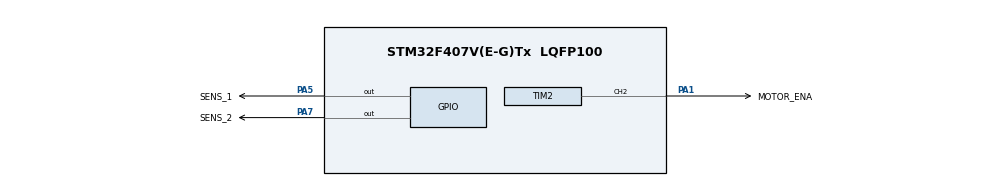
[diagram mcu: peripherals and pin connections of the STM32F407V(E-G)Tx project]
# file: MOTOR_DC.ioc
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Mcu.Family=STM32F4
Mcu.Name=STM32F407V(E-G)Tx
Mcu.Package=LQFP100
NVIC.PriorityGroup=NVIC_PRIORITYGROUP_0
PA1.GPIO_Label=MOTOR_ENA
PA1.Signal=S_TIM2_CH2
PA13.Mode=Serial_Wire
PA13.Signal=SYS_JTMS-SWDIO
PA14.Mode=Serial_Wire
PA14.Signal=SYS_JTCK-SWCLK
PA5.GPIO_Label=SENS_1
PA5.Signal=GPIO_Output
PA7.GPIO_Label=SENS_2
PA7.Signal=GPIO_Output
PH0-OSC_IN.Mode=HSE-External-Oscillator
PH0-OSC_IN.Signal=RCC_OSC_IN
PH1-OSC_OUT.Mode=HSE-External-Oscillator
PH1-OSC_OUT.Signal=RCC_OSC_OUT
ProjectManager.HeapSize=0x200
ProjectManager.StackSize=0x400
ProjectManager.TargetToolchain=STM32CubeIDE
RCC.48MHZClocksFreq_Value=48000000
RCC.AHBFreq_Value=168000000
RCC.APB1CLKDivider=RCC_HCLK_DIV4
RCC.APB1Freq_Value=42000000
RCC.APB1TimFreq_Value=84000000
RCC.APB2CLKDivider=RCC_HCLK_DIV2
RCC.APB2Freq_Value=84000000
RCC.APB2TimFreq_Value=168000000
RCC.CortexFreq_Value=168000000
RCC.HCLKFreq_Value=168000000
RCC.HSE_VALUE=8000000
RCC.HSI_VALUE=16000000
RCC.LSE_VALUE=32768
RCC.PLLM=8
RCC.PLLN=336
RCC.PLLQ=7
RCC.PLLSourceVirtual=RCC_PLLSOURCE_HSE
RCC.SYSCLKFreq_VALUE=168000000
RCC.SYSCLKSource=RCC_SYSCLKSOURCE_PLLCLK
RCC.VCOOutputFreq_Value=336000000
SH.S_TIM2_CH2.0=TIM2_CH2,PWM Generation2 CH2
TIM2.AutoReloadPreload=TIM_AUTORELOAD_PRELOAD_ENABLE
TIM2.Channel-PWM\ Generation2\ CH2=TIM_CHANNEL_2
TIM2.Period=625
TIM2.Prescaler=200
VP_TIM2_VS_ClockSourceINT.Mode=Internal
board=STM32F407G-DISC1

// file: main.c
#include "main.h"

/* USER CODE BEGIN Includes */
#include "string.h"
#include "stdlib.h"
#include "MOTOR_DC.h"
/* USER CODE END Includes */

TIM_HandleTypeDef htim2;

/* USER CODE BEGIN PV */
My_Motor_DC myMotor;
/* USER CODE END PV */

void SystemClock_Config(void);
static void MX_GPIO_Init(void);
static void MX_TIM2_Init(void);

int main(void)
{

  /* MCU Configuration--------------------------------------------------------*/

  /* Reset of all peripherals, Initializes the Flash interface and the Systick. */
  HAL_Init();

  /* Configure the system clock */
  SystemClock_Config();

  /* Initialize all configured peripherals */
  MX_GPIO_Init();
  MX_TIM2_Init();
  /* USER CODE BEGIN 2 */
  MOTOR_INIT(&myMotor, &htim2, TIM_CHANNEL_2, GPIOA, GPIO_PIN_7, GPIOA, GPIO_PIN_5);
  /* USER CODE END 2 */

  /* Infinite loop */
  /* USER CODE BEGIN WHILE */
  while (1)
  {
	  MOTOR_SETDIRECTION(&myMotor, MOTOR_DIRECTION_FORWARD);
	  MOTOR_RAMPSPEED(&myMotor, 255, 2000);
	  HAL_Delay(1000);
	  MOTOR_RAMPSPEED(&myMotor, 0, 1000);
	  HAL_Delay(500);
	  /* Reverse Direction */
	  MOTOR_SETDIRECTION(&myMotor, MOTOR_DIRECTION_BACKWARD);
	  MOTOR_SETSPEED(&myMotor, 150); /* Medium Speed Reverse */
	  HAL_Delay(2000);
	  /* Emergency Brake */
	  MOTOR_BRAKE(&myMotor);
	  HAL_Delay(1000);
    /* USER CODE END WHILE */

  }
}
